# NANO112AN_v1 register map
File version: 1.0
Registers are 32-bit, read-write, reset 0x0 unless marked. A register's access mark holds for its fields unless they carry their own. Offsets are from the block's base; [hi:lo] are bit positions; 'fields as' and 'values as' point back to an identical list.

## ACMP — ACMP Register Map
Base 0x401D0000
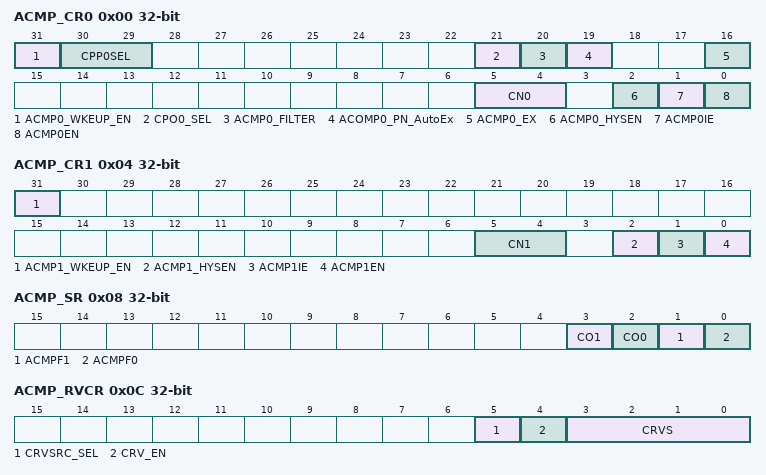
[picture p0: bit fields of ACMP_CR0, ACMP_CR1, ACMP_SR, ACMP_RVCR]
0x00 ACMP_CR0 — Analog Comparator 0 Control Register
  [31] ACMP0_WKEUP_EN — Comparator ACMP0 Wake-up Enable Control
    0=Wake-up function Disabled; 1=Wake-up function Enabled when the system enters Power-down mode
  [30:29] CPP0SEL — Comparator ACMP0 Positive Input Selection
    0=Input from PA.4; 1=Input from PA.3; 2=Input from PA.2; 3=Input from PA.1
  [21] CPO0_SEL — Comparator ACMP0 Output to Timer Path Selection
    0=Comparator ACMP0 output to Timer is through internal path; 1=Comparator ACMP0 output to Timer is through external pin (through PF.4)
  [20] ACMP0_FILTER — Comparator ACMP0 Output Filter
    0=Comparator ACMP0 output is not filtered by internal RC filter; 1=Comparator ACMP0 output is filtered by internal RC filter
  [19] ACOMP0_PN_AutoEx — Comparator Analog ACMP0_Px ACMP0_N Input Swap Function Automatically. This bit is only for sigma-delta ADC mode use.
    0=Disabled to swap comparator ACMP0 input function, ACMP0_Px and ACMP0_N, automatically; 1=Enabled to swap comparator ACMP0 input function, ACMP0_Px and ACMP0_N, automatically
  [16] ACMP0_EX — Comparator ACMP0 Swap. Note: This bit swaps the comparator inputs and inverts the comparator output.
    0=No swap to the comparator inputs and output; 1=Swap the comparator inputs with ACMP0_Px and ACMP0_N, and invert the polarity of comparator 0 output
  [5:4] CN0 — Comparator ACMP0 Negative Input Selection
    0=The comparator reference pin ACMP0_N is selected as the negative comparator input; 1=The internal comparator reference voltage (CRV) is selected as the negative comparator input; 2=The internal reference voltage (Int_VREF) is selected as the negative comparator input; 3=The AGND is selected as the negative comparator input
  [2] ACMP0_HYSEN — Comparator ACMP0 Hysteresis Enable Control
    0=ACMP0 Hysteresis function Disabled; 1=ACMP0 Hysteresis function Enabled. The typical range is 20mV
  [1] ACMP0IE — Comparator ACMP0 Interrupt Enable Control. Note: Interrupt generated if ACMP0IE bit is set to "1" after ACMP0 output changed.
    0=ACMP0 interrupt function Disabled; 1=ACMP0 interrupt function Enabled
  [0] ACMP0EN — Comparator ACMP0 Enable Control. Note: Comparator output needs to wait 10 us stable time after ACMP0EN is set.
    0=Disabled; 1=Enabled
0x04 ACMP_CR1 — Analog Comparator 1 Control Register
  [31] ACMP1_WKEUP_EN — Comparator ACMP1 Wake-up Enable Control
    values as ACMP_CR0.ACMP0_WKEUP_EN
  [5:4] CN1 — Comparator ACMP1 Negative Input Selection
    values as ACMP_CR0.CN0
  [2] ACMP1_HYSEN — Comparator ACMP1 Hysteresis Enable Control
    0=ACMP1 Hysteresis function Disabled; 1=ACMP1 Hysteresis function Enabled. The typical range is 20mV
  [1] ACMP1IE — Comparator ACMP1 Interrupt Enable Control. Note: Interrupt is generated if ACMP0IE bit is set to "1" after ACMP1 output changed.
    0=ACMP1 interrupt function Disabled; 1=ACMP1 interrupt function Enabled
  [0] ACMP1EN — Comparator ACMP1 Enable Control. Note: Comparator output needs to wait 10 us stable time after ACMP1EN is set.
    0=Disabled; 1=Enabled
0x08 ACMP_SR — Analog Comparator Status Register
  [3] CO1 — Comparator ACMP1 Output
  [2] CO0 — Comparator ACMP0 Output
  [1] ACMPF1 — Comparator ACMP1 Flag. This bit is set by hardware whenever the comparator 1 output changes state. This will generate an interrupt if ACMP1IE set. Note: Write "1" to clear this bit to 0.
  [0] ACMPF0 — Comparator ACMP0 Flag. This bit is set by hardware whenever the comparator 0 output changes state. This will generate an interrupt if ACMP0IE set. Note: Write "1" to clear this bit to 0.
0x0C ACMP_RVCR — Analog Comparator Reference Voltage Control Register
  [5] CRVSRC_SEL — CRV Source Selection
    0=From AVDD; 1=From Int_VREF
  [4] CRV_EN — CRV Enable Control
    0=CRV Disabled; 1=CRV Enabled
  [3:0] CRVS — Comparator Reference Voltage Setting
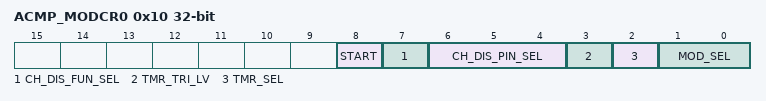
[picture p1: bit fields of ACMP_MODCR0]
0x10 ACMP_MODCR0 — Analog Comparator 0 Mode Control Register
  [8] START — Start ADC Mode
    0=Stop Sigma-Delta ADC Mode or Single Slope ADC Mode; 1=Start Sigma-Delta ADC Mode or Single Slope ADC Mode
  [7] CH_DIS_FUN_SEL — Charge or Discharge Pin Function Option. This bit is for Single Slope ADC Mode only.
    0=Drive low on charge pin to dis-charge capacitor and drive high on charge pin to charge capacitor; 1=Drive high on charge pin to dis-charge capacitor and drive low on charge pin to charge capacitor
  [6:4] CH_DIS_PIN_SEL — Charge or Discharge Pin Selection
    0=PA.1; 1=PA.2; 2=PA.3; 3=PA.4; 4=PA.5; 5=PA.6; 6=PA.14; 7=PF.5
  [3] TMR_TRI_LV — Timer Trigger Level. This bit is for Sigma-Delta ADC Mode.
    0=Comparator Output Low to High to Enable Timer; 1=Comparator Output High to Low to Enable Timer
  [2] TMR_SEL — Analog Comparator 0 Co-operation Timer Selection
    0=Select TIMER0 as co-operation Timer; 1=Select TIMER2 as co-operation Timer
  [1:0] MOD_SEL — Comparator Mode Selection
    0=Normal Comparator Mode; 1=Sigma-Delta ADC Mode; 2=Single Slope ADC Mode
